# STM32G051 register map
File version: 1.4
CPU: CM0 r0p1, little endian, MPU, no FPU, 2 interrupt priority bits
Registers are 32-bit, read-write, reset 0x0 unless marked. A register's access mark holds for its fields unless they carry their own. Offsets are from the block's base; [hi:lo] are bit positions.

## HDMI_CEC
Base 0x40007800
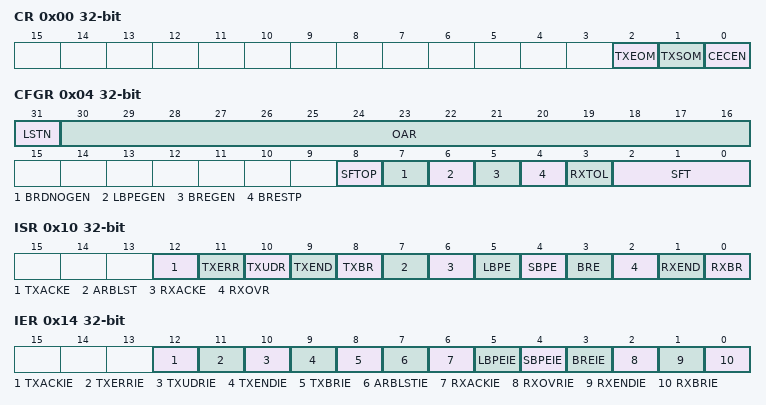
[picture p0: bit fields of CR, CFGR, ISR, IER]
0x00 CR — CEC control register
  [2] TXEOM — Tx end of message
  [1] TXSOM — Tx start of message
  [0] CECEN — CEC enable
0x04 CFGR — This register is used to configure the HDMI-CEC controller. It is mandatory to write CEC_CFGR only when CECEN=0.
  [31] LSTN — Listen mode LSTN bit is set and cleared by software.
  [30:16] OAR — Own addresses configuration
  [8] SFTOP — SFT option bit The SFTOPT bit is set and cleared by software.
  [7] BRDNOGEN — Avoid error-bit generation in broadcast
  [6] LBPEGEN — Generate error-bit on long bit period error
  [5] BREGEN — Generate error-bit on bit rising error
  [4] BRESTP — Rx-stop on bit rising error The BRESTP bit is set and cleared by software.
  [3] RXTOL — Rx-tolerance
  [2:0] SFT — Signal free time
0x08 TXDR wo — CEC Tx data register
  [7:0] TXD — Tx Data register. TXD is a write-only register containing the data byte to be transmitted. Note: TXD must be written when TXSTART=1
0x0C RXDR ro — CEC Rx Data Register
  [7:0] RXD — Rx Data register. RXD is read-only and contains the last data byte which has been received from the CEC line.
0x10 ISR — CEC Interrupt and Status Register
  [12] TXACKE — Tx-Missing Acknowledge Error In transmission mode, TXACKE is set by hardware to inform application that no acknowledge was received. In case of broadcast transmission, TXACKE informs application that a negative acknowledge was received. TXACKE aborts message transmission and clears TXSOM and TXEOM controls. TXACKE is cleared by software write at 1.
  [11] TXERR — Tx-Error In transmission mode, TXERR is set by hardware if the CEC initiator detects low impedance on the CEC line while it is released. TXERR aborts message transmission and clears TXSOM and TXEOM controls. TXERR is cleared by software write at 1.
  [10] TXUDR — Tx-Buffer Underrun In transmission mode, TXUDR is set by hardware if application was not in time to load TXDR before of next byte transmission. TXUDR aborts message transmission and clears TXSOM and TXEOM control bits. TXUDR is cleared by software write at 1
  [9] TXEND — End of Transmission TXEND is set by hardware to inform application that the last byte of the CEC message has been successfully transmitted. TXEND clears the TXSOM and TXEOM control bits. TXEND is cleared by software write at 1.
  [8] TXBR — Tx-Byte Request TXBR is set by hardware to inform application that the next transmission data has to be written to TXDR. TXBR is set when the 4th bit of currently transmitted byte is sent. Application must write the next byte to TXDR within 6 nominal data-bit periods before transmission underrun error occurs (TXUDR). TXBR is cleared by software write at 1.
  [7] ARBLST — Arbitration Lost ARBLST is set by hardware to inform application that CEC device is switching to reception due to arbitration lost event following the TXSOM command. ARBLST can be due either to a contending CEC device starting earlier or starting at the same time but with higher HEADER priority. After ARBLST assertion TXSOM bit keeps pending for next transmission attempt. ARBLST is cleared by software write at 1.
  [6] RXACKE — Rx-Missing Acknowledge In receive mode, RXACKE is set by hardware to inform application that no acknowledge was seen on the CEC line. RXACKE applies only for broadcast messages and in listen mode also for not directly addressed messages (destination address not enabled in OAR). RXACKE aborts message reception. RXACKE is cleared by software write at 1.
  [5] LBPE — Rx-Long Bit Period Error LBPE is set by hardware in case a Data-Bit waveform is detected with Long Bit Period Error. LBPE is set at the end of the maximum bit-extension tolerance allowed by RXTOL, in case falling edge is still longing. LBPE always stops reception of the CEC message. LBPE generates an Error-Bit on the CEC line if LBPEGEN=1. In case of broadcast, Error-Bit is generated even in case of LBPEGEN=0. LBPE is cleared by software write at 1.
  [4] SBPE — Rx-Short Bit Period Error SBPE is set by hardware in case a Data-Bit waveform is detected with Short Bit Period Error. SBPE is set at the time the anticipated falling edge occurs. SBPE generates an Error-Bit on the CEC line. SBPE is cleared by software write at 1.
  [3] BRE — Rx-Bit Rising Error BRE is set by hardware in case a Data-Bit waveform is detected with Bit Rising Error. BRE is set either at the time the misplaced rising edge occurs, or at the end of the maximum BRE tolerance allowed by RXTOL, in case rising edge is still longing. BRE stops message reception if BRESTP=1. BRE generates an Error-Bit on the CEC line if BREGEN=1. BRE is cleared by software write at 1.
  [2] RXOVR — Rx-Overrun RXOVR is set by hardware if RXBR is not yet cleared at the time a new byte is received on the CEC line and stored into RXD. RXOVR assertion stops message reception so that no acknowledge is sent. In case of broadcast, a negative acknowledge is sent. RXOVR is cleared by software write at 1.
  [1] RXEND — End Of Reception RXEND is set by hardware to inform application that the last byte of a CEC message is received from the CEC line and stored into the RXD buffer. RXEND is set at the same time of RXBR. RXEND is cleared by software write at 1.
  [0] RXBR — Rx-Byte Received The RXBR bit is set by hardware to inform application that a new byte has been received from the CEC line and stored into the RXD buffer. RXBR is cleared by software write at 1.
0x14 IER — CEC interrupt enable register
  [12] TXACKIE — Tx-missing acknowledge error interrupt enable The TXACKEIE bit is set and cleared by software.
  [11] TXERRIE — Tx-error interrupt enable The TXERRIE bit is set and cleared by software.
  [10] TXUDRIE — Tx-underrun interrupt enable The TXUDRIE bit is set and cleared by software.
  [9] TXENDIE — Tx-end of message interrupt enable The TXENDIE bit is set and cleared by software.
  [8] TXBRIE — Tx-byte request interrupt enable The TXBRIE bit is set and cleared by software.
  [7] ARBLSTIE — Arbitration lost interrupt enable The ARBLSTIE bit is set and cleared by software.
  [6] RXACKIE — Rx-missing acknowledge error interrupt enable The RXACKIE bit is set and cleared by software.
  [5] LBPEIE — Long bit period error interrupt enable The LBPEIE bit is set and cleared by software.
  [4] SBPEIE — Short bit period error interrupt enable The SBPEIE bit is set and cleared by software.
  [3] BREIE — Bit rising error interrupt enable The BREIE bit is set and cleared by software.
  [2] RXOVRIE — Rx-buffer overrun interrupt enable The RXOVRIE bit is set and cleared by software.
  [1] RXENDIE — End of reception interrupt enable The RXENDIE bit is set and cleared by software.
  [0] RXBRIE — Rx-byte received interrupt enable The RXBRIE bit is set and cleared by software.
